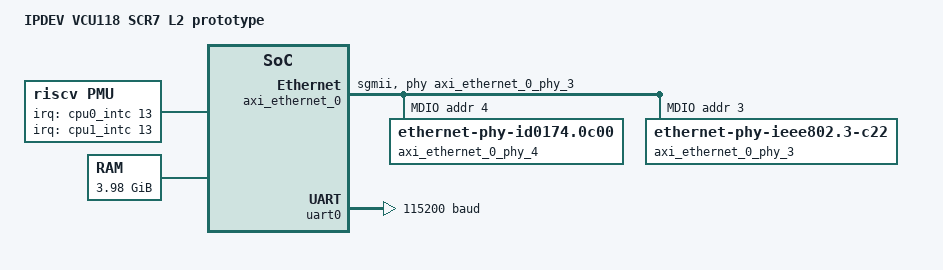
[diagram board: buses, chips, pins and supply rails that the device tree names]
/dts-v1/;
/ {
 cpus {
  #address-cells = <1>;
  #size-cells = <0>;
  cpu0: cpu@0 {
   reg = <0>;
   device_type = "cpu";
   status = "okay";
   next-level-cache = <&l2>;
   compatible = "syntacore,scr7", "riscv";
   riscv,isa = "rv64imafdc_zba_zbb_zbc_zbs_sscofpmf";
   riscv,isa-base = "rv64i";
   riscv,isa-extensions = "i", "m", "a", "f", "d", "c", "zba", "zbb", "zbc", "zbs", "sscofpmf";
   mmu-type = "riscv,sv39";
   d-cache-block-size = <16>;
   d-cache-sets = <256>;
   d-cache-size = <32768>;
   i-cache-block-size = <16>;
   i-cache-sets = <256>;
   i-cache-size = <32768>;
   riscv,cbom-block-size = <32>;
   opensbi-domain = <&tdomain>;
   clock-frequency = <50000000>;
   cpu0_intc: interrupt-controller {
    compatible = "riscv,cpu-intc";
    interrupt-controller;
    #interrupt-cells = <1>;
    #address-cells = <0>;
   };
  };
  cpu1: cpu@1 {
   reg = <1>;
   device_type = "cpu";
   status = "okay";
   next-level-cache = <&l2>;
   compatible = "syntacore,scr7", "riscv";
   riscv,isa = "rv64imafdc_zba_zbb_zbc_zbs_sscofpmf";
   riscv,isa-base = "rv64i";
   riscv,isa-extensions = "i", "m", "a", "f", "d", "c", "zba", "zbb", "zbc", "zbs", "sscofpmf";
   mmu-type = "riscv,sv39";
   d-cache-block-size = <16>;
   d-cache-sets = <256>;
   d-cache-size = <32768>;
   i-cache-block-size = <16>;
   i-cache-sets = <256>;
   i-cache-size = <32768>;
   riscv,cbom-block-size = <32>;
   opensbi-domain = <&tdomain>;
   clock-frequency = <50000000>;
   cpu1_intc: interrupt-controller {
    compatible = "riscv,cpu-intc";
    interrupt-controller;
    #interrupt-cells = <1>;
    #address-cells = <0>;
   };
  };
  cpu2: cpu@2 {
   reg = <2>;
   device_type = "cpu";
   status = "okay";
   next-level-cache = <&l2>;
   compatible = "syntacore,scr7", "riscv";
   riscv,isa = "rv64imafdc_zba_zbb_zbc_zbs_sscofpmf";
   riscv,isa-base = "rv64i";
   riscv,isa-extensions = "i", "m", "a", "f", "d", "c", "zba", "zbb", "zbc", "zbs", "sscofpmf";
   mmu-type = "riscv,sv39";
   d-cache-block-size = <16>;
   d-cache-sets = <256>;
   d-cache-size = <32768>;
   i-cache-block-size = <16>;
   i-cache-sets = <256>;
   i-cache-size = <32768>;
   riscv,cbom-block-size = <32>;
   opensbi-domain = <&tdomain>;
   clock-frequency = <50000000>;
   cpu2_intc: interrupt-controller {
    compatible = "riscv,cpu-intc";
    interrupt-controller;
    #interrupt-cells = <1>;
    #address-cells = <0>;
   };
  };
  cpu3: cpu@3 {
   reg = <3>;
   device_type = "cpu";
   status = "okay";
   next-level-cache = <&l2>;
   compatible = "syntacore,scr7", "riscv";
   riscv,isa = "rv64imafdc_zba_zbb_zbc_zbs_sscofpmf";
   riscv,isa-base = "rv64i";
   riscv,isa-extensions = "i", "m", "a", "f", "d", "c", "zba", "zbb", "zbc", "zbs", "sscofpmf";
   mmu-type = "riscv,sv39";
   d-cache-block-size = <16>;
   d-cache-sets = <256>;
   d-cache-size = <32768>;
   i-cache-block-size = <16>;
   i-cache-sets = <256>;
   i-cache-size = <32768>;
   riscv,cbom-block-size = <32>;
   opensbi-domain = <&tdomain>;
   clock-frequency = <50000000>;
   cpu3_intc: interrupt-controller {
    compatible = "riscv,cpu-intc";
    interrupt-controller;
    #interrupt-cells = <1>;
    #address-cells = <0>;
   };
  };
  cpu4: cpu@4 {
   reg = <4>;
   device_type = "cpu";
   status = "okay";
   next-level-cache = <&l2>;
   compatible = "syntacore,scr7", "riscv";
   riscv,isa = "rv64imafdc_zba_zbb_zbc_zbs_sscofpmf";
   riscv,isa-base = "rv64i";
   riscv,isa-extensions = "i", "m", "a", "f", "d", "c", "zba", "zbb", "zbc", "zbs", "sscofpmf";
   mmu-type = "riscv,sv39";
   d-cache-block-size = <16>;
   d-cache-sets = <256>;
   d-cache-size = <32768>;
   i-cache-block-size = <16>;
   i-cache-sets = <256>;
   i-cache-size = <32768>;
   riscv,cbom-block-size = <32>;
   opensbi-domain = <&tdomain>;
   clock-frequency = <50000000>;
   cpu4_intc: interrupt-controller {
    compatible = "riscv,cpu-intc";
    interrupt-controller;
    #interrupt-cells = <1>;
    #address-cells = <0>;
   };
  };
  cpu5: cpu@5 {
   reg = <5>;
   device_type = "cpu";
   status = "okay";
   next-level-cache = <&l2>;
   compatible = "syntacore,scr7", "riscv";
   riscv,isa = "rv64imafdc_zba_zbb_zbc_zbs_sscofpmf";
   riscv,isa-base = "rv64i";
   riscv,isa-extensions = "i", "m", "a", "f", "d", "c", "zba", "zbb", "zbc", "zbs", "sscofpmf";
   mmu-type = "riscv,sv39";
   d-cache-block-size = <16>;
   d-cache-sets = <256>;
   d-cache-size = <32768>;
   i-cache-block-size = <16>;
   i-cache-sets = <256>;
   i-cache-size = <32768>;
   riscv,cbom-block-size = <32>;
   opensbi-domain = <&tdomain>;
   clock-frequency = <50000000>;
   cpu5_intc: interrupt-controller {
    compatible = "riscv,cpu-intc";
    interrupt-controller;
    #interrupt-cells = <1>;
    #address-cells = <0>;
   };
  };
  cpu6: cpu@6 {
   reg = <6>;
   device_type = "cpu";
   status = "okay";
   next-level-cache = <&l2>;
   compatible = "syntacore,scr7", "riscv";
   riscv,isa = "rv64imafdc_zba_zbb_zbc_zbs_sscofpmf";
   riscv,isa-base = "rv64i";
   riscv,isa-extensions = "i", "m", "a", "f", "d", "c", "zba", "zbb", "zbc", "zbs", "sscofpmf";
   mmu-type = "riscv,sv39";
   d-cache-block-size = <16>;
   d-cache-sets = <256>;
   d-cache-size = <32768>;
   i-cache-block-size = <16>;
   i-cache-sets = <256>;
   i-cache-size = <32768>;
   riscv,cbom-block-size = <32>;
   opensbi-domain = <&tdomain>;
   clock-frequency = <50000000>;
   cpu6_intc: interrupt-controller {
    compatible = "riscv,cpu-intc";
    interrupt-controller;
    #interrupt-cells = <1>;
    #address-cells = <0>;
   };
  };
  cpu7: cpu@7 {
   reg = <7>;
   device_type = "cpu";
   status = "okay";
   next-level-cache = <&l2>;
   compatible = "syntacore,scr7", "riscv";
   riscv,isa = "rv64imafdc_zba_zbb_zbc_zbs_sscofpmf";
   riscv,isa-base = "rv64i";
   riscv,isa-extensions = "i", "m", "a", "f", "d", "c", "zba", "zbb", "zbc", "zbs", "sscofpmf";
   mmu-type = "riscv,sv39";
   d-cache-block-size = <16>;
   d-cache-sets = <256>;
   d-cache-size = <32768>;
   i-cache-block-size = <16>;
   i-cache-sets = <256>;
   i-cache-size = <32768>;
   riscv,cbom-block-size = <32>;
   opensbi-domain = <&tdomain>;
   clock-frequency = <50000000>;
   cpu7_intc: interrupt-controller {
    compatible = "riscv,cpu-intc";
    interrupt-controller;
    #interrupt-cells = <1>;
    #address-cells = <0>;
   };
  };
  l2: l2-cache {
   compatible = "cache";
   cache-unified;
   cache-size = <0x20000>;
   cache-sets = <256>;
   cache-block-size = <64>;
   cache-level = <2>;
  };
 };
 pmu: pmu {
  compatible = "riscv,pmu";
  interrupts-extended = <
   &cpu0_intc 13
   &cpu1_intc 13
   &cpu2_intc 13
   &cpu3_intc 13
   &cpu4_intc 13
   &cpu5_intc 13
   &cpu6_intc 13
   &cpu7_intc 13
  >;
  riscv,event-to-mhpmcounters =
   <0x01 0x06 0xFFFFFFF8>,
   <0x08 0x09 0xFFFFFFF8>,
   <0x10000 0x10001 0xFFFFFFF8>,
   <0x10004 0x10005 0xFFFFFFF8>,
   <0x10008 0x10009 0xFFFFFFF8>,
   <0x1000c 0x1000d 0xFFFFFFF8>,
   <0x10018 0x10019 0xFFFFFFF8>,
   <0x10028 0x10029 0xFFFFFFF8>;
  riscv,event-to-mhpmevent =
   <0x01 0x00000000 0x0000001>,
   <0x02 0x00000000 0x0000021>,
   <0x03 0x00000000 0x0000005>,
   <0x04 0x00000000 0x0000015>,
   <0x05 0x00000000 0x0000012>,
   <0x06 0x00000000 0x0000092>,
   <0x08 0x00000000 0x0000083>,
   <0x09 0x00000000 0x00000e3>,
   <0x10000 0x00000000 0x00000d5>,
   <0x10001 0x00000000 0x0000015>,
   <0x10004 0x00000000 0x0000019>,
   <0x10005 0x00000000 0x0000055>,
   <0x10009 0x00000000 0x0000014>,
   <0x1000d 0x00000000 0x0000044>,
   <0x10018 0x00000000 0x0000065>,
   <0x10019 0x00000000 0x0000075>,
   <0x10028 0x00000000 0x0000012>,
   <0x10029 0x00000000 0x0000092>;
  riscv,raw-event-to-mhpmcounters =
   <0x00000000 0x0000001 0xffffffff 0xffffff0f 0xFFFFFFF8>,
   <0x00000000 0x0000002 0xffffffff 0xffffff0f 0xFFFFFFF8>,
   <0x00000000 0x0000003 0xffffffff 0xfffffe0f 0xFFFFFFF8>,
   <0x00000000 0x0000004 0xffffffff 0xfffffe0f 0xFFFFFFF8>,
   <0x00000000 0x0000005 0xffffffff 0xfffffe0f 0xFFFFFFF8>,
   <0x00000000 0x0000006 0xffffffff 0xffffff0f 0xFFFFFFF8>,
   <0x00000000 0x0000007 0xffffffff 0xffffff0f 0xFFFFFFF8>,
   <0x00000000 0x0000008 0xffffffff 0xfffffe0f 0xFFFFFFF8>,
   <0x00000000 0x0000009 0xffffffff 0xffffff0f 0xFFFFFFF8>,
   <0x00000000 0x000000a 0xffffffff 0xffffff0f 0xFFFFFFF8>,
   <0x00000000 0x000000b 0xffffffff 0xfffffe0f 0xFFFFFFF8>;
 };
};
/ {
 compatible = "syntacore,scr_sdk";
 #address-cells = <2>;
 #size-cells = <2>;
 chosen {
  opensbi-domains {
   compatible = "opensbi,domain,config";
   mcfg_reg: mcfg_reg {
    compatible = "opensbi,domain,memregion";
    base = <0xffffff 0xf0040000>;
    order = <13>;
    mmio;
   };
   dram_reg: dram_reg {
    compatible = "opensbi,domain,memregion";
    base = <0x0 0x0>;
    order = <32>;
   };
   dma_reg: dma_reg {
    compatible = "opensbi,domain,memregion";
    base = <0x00 0xff000000>;
    order = <24>;
    mmio;
   };
   mmio_reg: mmio_reg {
    compatible = "opensbi,domain,memregion";
    base = <0xffffff 0xff000000>;
    devices = <&uart0>;
    order = <23>;
    mmio;
   };
   plic_reg: plic_reg {
    compatible = "opensbi,domain,memregion";
    base = <0xffffff 0xfe000000>;
    devices = <&plic>;
    order = <25>;
    mmio;
   };
   tdomain: trusted-domain {
    compatible = "opensbi,domain,instance";
    possible-harts = <
     &cpu0
     &cpu1
     &cpu2
     &cpu3
     &cpu4
     &cpu5
     &cpu6
     &cpu7
    >;
    regions =
     <&dma_reg ((1UL << 0) | (1UL << 1) |
         (1UL << 3) | (1UL << 4) |
         ((((1) & 3) << 16) | (1 << 29)))>,
     <&dram_reg ((1UL << 0) | (1UL << 1) | (1UL << 2) |
          (1UL << 3) | (1UL << 4) | (1UL << 5))>,
     <&mcfg_reg ((1UL << 0) | (1UL << 1) |
          (1UL << 3) |
          ((((3) & 3) << 16) | (1 << 29)))>,
     <&mmio_reg ((1UL << 0) | (1UL << 1) |
          (1UL << 3) | (1UL << 4) |
          ((((1) & 3) << 16) | (1 << 29)))>,
     <&plic_reg ((1UL << 0) | (1UL << 1) |
          (1UL << 3) | (1UL << 4) |
          ((((1) & 3) << 16) | (1 << 29)))>;
    system-reset-allowed;
    system-suspend-allowed;
   };
  };
  scr-root-domain {
   #address-cells = <2>;
   #size-cells = <2>;
   compatible = "syntacore,root-domain";
   ocram@ffffffffffff0000 {
    reg = <0xffffffff 0xffff0000 0x00 0x8000>;
    flags = <((1UL << 0) | (1UL << 1))>;
   };
  };
 };
 memory@0 {
  reg = <0x00 0x00 0x00 0xff000000>;
  device_type = "memory";
 };
 reserved-memory {
  ranges;
  #address-cells = <2>;
  #size-cells = <2>;
  linux,dma@0 {
   compatible = "shared-dma-pool";
   reg = <0x00 0xff000000 0x00 0x1000000>;
   linux,dma-default;
   no-map;
  };
 };
 clocks {
  sysclk: clk {
   compatible = "fixed-clock";
   #clock-cells = <0x00>;
   clock-frequency = <50000000>;
  };
 };
 firmware {
  syntacore,bldid = "0000000000000000";
 };
 scr-fpga-reg {
  compatible = "syntacore,fpga-reg-v1";
  syntacore,buildid-reg = <0xffffff 0xff000000>;
  syntacore,sysclk-reg = <0xffffff 0xff001000>;
  syntacore,clsclk-reg = <0xffffff 0xff001000>;
 };
 soc {
  compatible = "simple-bus";
  device_type = "soc";
  ranges;
  #address-cells = <2>;
  #size-cells = <2>;
  bus-frequency = <50000000>;
  dma-noncoherent;
  cluster_bus: cluster_bus {
   compatible = "simple-bus";
   ranges;
   #address-cells = <2>;
   #size-cells = <2>;
   iccm: iccm {
    compatible = "syntacore,iccm";
    mbox-mapping = <
     &cpu0 0
     &cpu1 1
     &cpu2 2
     &cpu3 3
     &cpu4 4
     &cpu5 5
     &cpu6 6
     &cpu7 7
    >;
   };
   mtimer: timer@fffffff0040000 {
    compatible = "syntacore,mtimer";
    reg = <0xffffff 0xf0040000 0 0x1000>;
    clock-frequency = <50000000>;
    interrupts-extended = <
     &cpu0_intc 7
     &cpu1_intc 7
     &cpu2_intc 7
     &cpu3_intc 7
     &cpu4_intc 7
     &cpu5_intc 7
     &cpu6_intc 7
     &cpu7_intc 7
    >;
   };
   plic: interrupt-controller@fffffffe000000 {
    compatible = "syntacore,plic";
    reg = <0xffffff 0xfe000000 0 0x1000000>;
    reg-names = "control";
    #interrupt-cells = <2>;
    interrupt-controller;
    interrupts-extended = <
     &cpu0_intc 11 &cpu0_intc 9
     &cpu1_intc 11 &cpu1_intc 9
     &cpu2_intc 11 &cpu2_intc 9
     &cpu3_intc 11 &cpu3_intc 9
     &cpu4_intc 11 &cpu4_intc 9
     &cpu5_intc 11 &cpu5_intc 9
     &cpu6_intc 11 &cpu6_intc 9
     &cpu7_intc 11 &cpu7_intc 9
    >;
    riscv,ndev = <16>;
    riscv,max-priority = <7>;
   };
   scr_l2_cache: cache-controller@fffffff0041000 {
    compatible = "syntacore,l2-cache";
    reg = <0xffffff 0xf0041000 0 0x1000>;
   };
  };
  axi_ethernet_0: ethernet@ffffffff040000 {
   compatible = "xlnx,axi-ethernet-1.00.a";
   reg = <0xffffff 0xff040000 0x00 0x40000>;
   device_type = "network";
   local-mac-address = [00 0a 35 04 D0 99];
   phy-handle = <&axi_ethernet_0_phy_3>;
   pcs-handle = <&axi_ethernet_0_phy_4>;
   phy-mode = "sgmii";
   managed = "in-band-status";
   xlnx,rxmem = <0x1000>;
   xlnx,rxcsum = <0x2>;
   xlnx,txcsum = <0x2>;
   axistream-connected = <&axi_ethernet_0_dma>;
   axistream-control-connected = <&axi_ethernet_0_dma>;
   mdio {
    #address-cells = <1>;
    #size-cells = <0>;
    axi_ethernet_0_phy_4: phy@4 {
     compatible = "ethernet-phy-id0174.0c00";
     reg = <4>;
    };
    axi_ethernet_0_phy_3: phy@3 {
     compatible = "ethernet-phy-ieee802.3-c22";
     reg = <3>;
     ti,fifo-depth = <0x3>;
     ti,sgmii-ref-clock-output-enable = <1>;
     ti,dp83867-rxctrl-strap-quirk = <1>;
    };
   };
  };
  axi_ethernet_0_dma: dma@ffffffff080000 {
   compatible = "xlnx,eth-dma";
   reg = <0xffffff 0xff080000 0x00 0x10000>;
   #dma-cells = <1>;
   clock-names = "s_axi_lite_aclk";
   axistream-connected = <&axi_ethernet_0>;
   axistream-control-connected = <&axi_ethernet_0>;
   xlnx,include-dre;
   interrupt-parent = <&plic>;
   interrupts = <3 4>, <2 4>;
   clocks = <&sysclk>;
   clock-frequency = <50000000>;
  };
  uart0: serial@ffffffff010000 {
   compatible = "ns16550a";
   reg = <0xffffff 0xff010000 0x00 0x1000>;
   reg-io-width = <4>;
   reg-shift = <2>;
   current-speed = <115200>;
   interrupt-parent = <&plic>;
   interrupts = <1 4>;
   clocks = <&sysclk>;
   clock-frequency = <50000000>;
  };
 };
};
/ {
 model = "IPDEV VCU118 SCR7 L2 prototype";
 aliases {
  ethernet = &axi_ethernet_0;
  serial = &uart0;
 };
 chosen {
  bootargs = "earlycon=sbi console=ttyS0,115200 initrdmem=0x30000000,512M net.ifnames=0 swiotlb=noforce";
  stdout-path = "serial";
 };
 cpus {
  timebase-frequency = <1000000>;
 };
};
